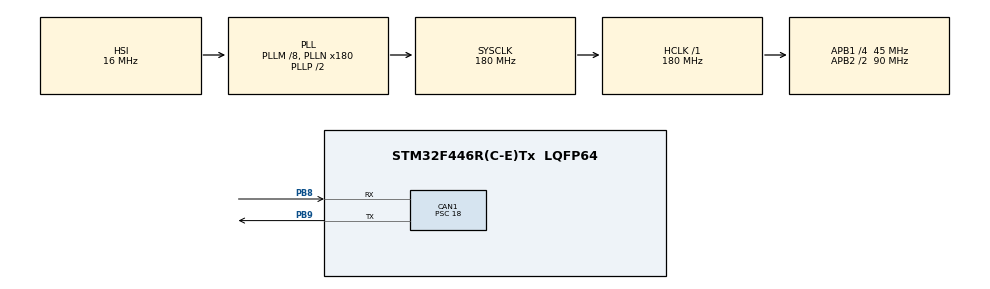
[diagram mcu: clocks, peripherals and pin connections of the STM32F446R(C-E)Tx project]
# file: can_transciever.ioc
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CAN1.BS1=CAN_BS1_2TQ
CAN1.BS2=CAN_BS2_2TQ
CAN1.CalculateBaudRate=500000
CAN1.CalculateTimeBit=2000
CAN1.CalculateTimeQuantum=400.0
CAN1.Mode=CAN_MODE_NORMAL
CAN1.Prescaler=18
CAN1.TXFP=DISABLE
Mcu.Family=STM32F4
Mcu.Name=STM32F446R(C-E)Tx
Mcu.Package=LQFP64
NVIC.CAN1_RX0_IRQn=true\:5\:0\:true\:false\:true\:true\:true\:true
NVIC.PriorityGroup=NVIC_PRIORITYGROUP_4
PA13.Mode=Serial_Wire
PA13.Signal=SYS_JTMS-SWDIO
PA14.Mode=Serial_Wire
PA14.Signal=SYS_JTCK-SWCLK
PB8.Mode=CAN_Activate
PB8.Signal=CAN1_RX
PB9.Mode=CAN_Activate
PB9.Signal=CAN1_TX
ProjectManager.HeapSize=0x200
ProjectManager.StackSize=0x400
ProjectManager.TargetToolchain=STM32CubeIDE
RCC.AHBFreq_Value=180000000
RCC.APB1CLKDivider=RCC_HCLK_DIV4
RCC.APB1Freq_Value=45000000
RCC.APB1TimFreq_Value=90000000
RCC.APB2CLKDivider=RCC_HCLK_DIV2
RCC.APB2Freq_Value=90000000
RCC.APB2TimFreq_Value=180000000
RCC.CortexFreq_Value=180000000
RCC.HCLKFreq_Value=180000000
RCC.PLLM=8
RCC.PLLN=180
RCC.SYSCLKFreq_VALUE=180000000
RCC.SYSCLKSource=RCC_SYSCLKSOURCE_PLLCLK
RCC.USBFreq_Value=180000000
RCC.VCOOutputFreq_Value=360000000
board=custom

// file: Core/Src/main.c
/* USER CODE BEGIN Header */
/**
  ******************************************************************************
  * @file           : main.c
  * @brief          : Main program body
  ******************************************************************************
  * @attention
  *
  * Copyright (c) 2024 STMicroelectronics.
  * All rights reserved.
  *
  * This software is licensed under terms that can be found in the LICENSE file
  * in the root directory of this software component.
  * If no LICENSE file comes with this software, it is provided AS-IS.
  *
  ******************************************************************************
  */
/* USER CODE END Header */
#include "main.h"
#include "can.h"
#include "gpio.h"

void SystemClock_Config(void);

/* USER CODE BEGIN 0 */

CAN_TxHeaderTypeDef TxHeader;
CAN_RxHeaderTypeDef RxHeader;

uint8_t TxData[8];
uint8_t RxData[8];

uint32_t TxMailbox;

uint32_t count;
uint32_t can_ok_count;
HAL_StatusTypeDef can_res;
HAL_StatusTypeDef can_res_rx;

//void HAL_CAN_RxFifo1MsgPendingCallback (CAN_HandleTypeDef *hcan){
//	HAL_CAN_GetRxMessage(hcan, CAN_RX_FIFO1, &RxHeader, RxData);
//	count++;
//}

void HAL_CAN_RxFifo0MsgPendingCallback (CAN_HandleTypeDef *hcan){
	HAL_CAN_GetRxMessage(hcan, CAN_RX_FIFO0, &RxHeader, RxData);
	count++;
}

/* USER CODE END 0 */

int main(void)
{

  /* MCU Configuration--------------------------------------------------------*/

  /* Reset of all peripherals, Initializes the Flash interface and the Systick. */
  HAL_Init();

  /* Configure the system clock */
  SystemClock_Config();

  /* Initialize all configured peripherals */
  MX_GPIO_Init();
  MX_CAN1_Init();
  /* USER CODE BEGIN 2 */
  HAL_CAN_Start(&hcan1);

  HAL_CAN_ActivateNotification(&hcan1, CAN_IT_RX_FIFO0_MSG_PENDING);

  TxHeader.DLC = 8;
  TxHeader.ExtId = 0;
  TxHeader.IDE = CAN_ID_STD;
  TxHeader.RTR = CAN_RTR_DATA;
  TxHeader.StdId = 0x446;
  // TxHeader.TransmitGlobalTime = DISABLE;

  TxData[0] = 0xf3;
  TxData[1] = 0xf3;
  TxData[2] = 0xf3;
  TxData[3] = 0xf3;
  TxData[4] = 0xf3;
  TxData[5] = 0xf3;
  TxData[6] = 0xf3;
  TxData[7] = 0xf3;

  /* USER CODE END 2 */

  /* Infinite loop */
  /* USER CODE BEGIN WHILE */
  while (1)
  {
	  can_res = HAL_CAN_AddTxMessage(&hcan1, &TxHeader, TxData, &TxMailbox);
	  HAL_Delay(100);
	  if (can_res == HAL_OK)
		  can_ok_count++;
	  // can_res_rx = HAL_CAN_GetRxMessage(&hcan1, CAN_RX_FIFO1, &RxHeader, RxData);
    /* USER CODE END WHILE */

  }
}

void SystemClock_Config(void)
{
  RCC_OscInitTypeDef RCC_OscInitStruct = {0};
  RCC_ClkInitTypeDef RCC_ClkInitStruct = {0};

  /** Configure the main internal regulator output voltage
  */
  __HAL_RCC_PWR_CLK_ENABLE();
  __HAL_PWR_VOLTAGESCALING_CONFIG(PWR_REGULATOR_VOLTAGE_SCALE1);

  /** Initializes the RCC Oscillators according to the specified parameters
  * in the RCC_OscInitTypeDef structure.
  */
  RCC_OscInitStruct.OscillatorType = RCC_OSCILLATORTYPE_HSI;
  RCC_OscInitStruct.HSIState = RCC_HSI_ON;
  RCC_OscInitStruct.HSICalibrationValue = RCC_HSICALIBRATION_DEFAULT;
  RCC_OscInitStruct.PLL.PLLState = RCC_PLL_ON;
  RCC_OscInitStruct.PLL.PLLSource = RCC_PLLSOURCE_HSI;
  RCC_OscInitStruct.PLL.PLLM = 8;
  RCC_OscInitStruct.PLL.PLLN = 180;
  RCC_OscInitStruct.PLL.PLLP = RCC_PLLP_DIV2;
  RCC_OscInitStruct.PLL.PLLQ = 2;
  RCC_OscInitStruct.PLL.PLLR = 2;
  if (HAL_RCC_OscConfig(&RCC_OscInitStruct) != HAL_OK)
  {
    Error_Handler();
  }

  /** Activate the Over-Drive mode
  */
  if (HAL_PWREx_EnableOverDrive() != HAL_OK)
  {
    Error_Handler();
  }

  /** Initializes the CPU, AHB and APB buses clocks
  */
  RCC_ClkInitStruct.ClockType = RCC_CLOCKTYPE_HCLK|RCC_CLOCKTYPE_SYSCLK
                              |RCC_CLOCKTYPE_PCLK1|RCC_CLOCKTYPE_PCLK2;
  RCC_ClkInitStruct.SYSCLKSource = RCC_SYSCLKSOURCE_PLLCLK;
  RCC_ClkInitStruct.AHBCLKDivider = RCC_SYSCLK_DIV1;
  RCC_ClkInitStruct.APB1CLKDivider = RCC_HCLK_DIV4;
  RCC_ClkInitStruct.APB2CLKDivider = RCC_HCLK_DIV2;

  if (HAL_RCC_ClockConfig(&RCC_ClkInitStruct, FLASH_LATENCY_5) != HAL_OK)
  {
    Error_Handler();
  }
}

void Error_Handler(void)
{
  __disable_irq();
  while (1)
  {
  }
}
